# GD32A72_A74x register map
File version: 1.0
CPU: CM7 r2p1, little endian, MPU, FPU, DSP, 4 interrupt priority bits
Registers are 32-bit, read-write, reset 0x0 unless marked. A register's access mark holds for its fields unless they carry their own. Offsets are from the block's base; [hi:lo] are bit positions; {n}, {i} and the like mark numbered series.

## HSMIF
Base 0x49008C00
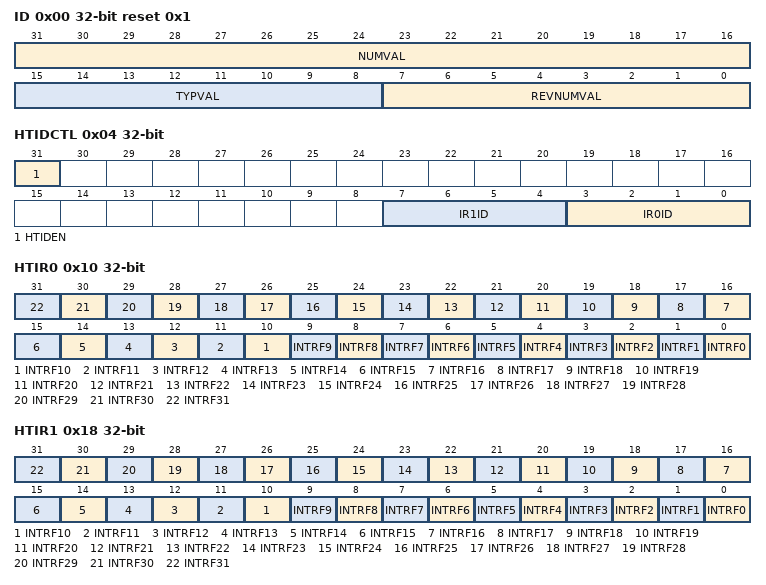
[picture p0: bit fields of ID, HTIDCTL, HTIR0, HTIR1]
0x00 ID ro reset 0x1 — Identifier register
  [31:16] NUMVAL — the value of the id number
  [15:8] TYPVAL — the value of the type
  [7:0] REVNUMVAL — the value of the type revision number
0x04 HTIDCTL ro — Host identifier control register
  [31] HTIDEN — host id enable
  [7:4] IR1ID — interrupt request1 id
  [3:0] IR0ID — interrupt request0 id
0x10 HTIR0 — Host interrupt request register0
  [n] INTRF{n} (n=0..31) — interrupt request flag {n}
0x18 HTIR1 — Host interrupt request register1
  [n] INTRF{n} (n=0..31) — interrupt request flag {n}
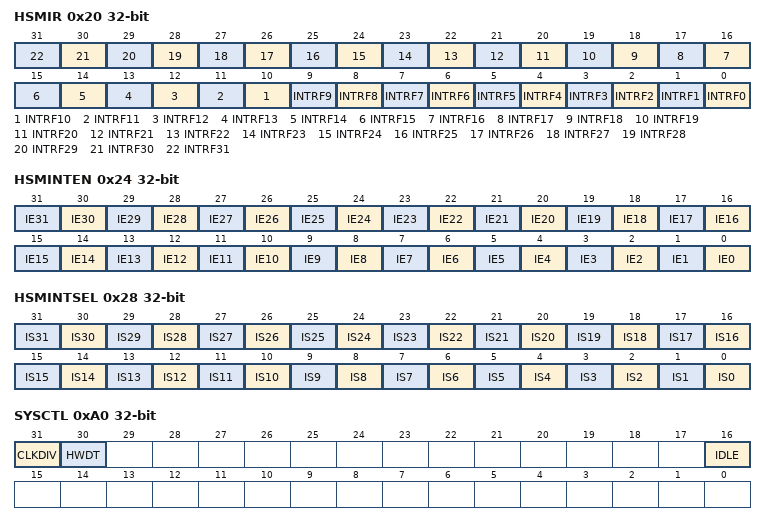
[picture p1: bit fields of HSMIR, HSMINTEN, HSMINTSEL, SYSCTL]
0x20 HSMIR — HSM interrupt request register
  [n] INTRF{n} (n=0..31) — interrupt request flag {n}
0x24 HSMINTEN — HSM interrupt enable register
  [n] IE{n} (n=0..31) — interrupt enable {n}
0x28 HSMINTSEL — HSM interrupt select register
  [n] IS{n} (n=0..31) — interrupt select {n}
0x40 HSMSTAT ro — HSM status register
  [31:0] STAT — status
0x48 HTSTAT — Host status register
  [31:0] STAT — status
0xA0 SYSCTL ro — System control register
  [31] CLKDIV — clock division
  [30] HWDT — HWDT widget
  [16] IDLE — idle state
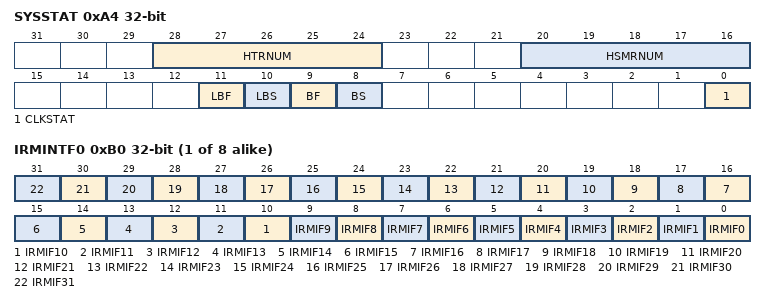
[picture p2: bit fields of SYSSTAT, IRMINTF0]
0xA4 SYSSTAT ro — System status register
  [28:24] HTRNUM — these bits indicate the number of host has performed software recovery in a power on reset (por) cycle
  [20:16] HSMRNUM — these bits indicate the number of hsm has performed software recovery in a power on reset (por) cycle
  [11] LBF — last boot failure flag
  [10] LBS — last boot success flag
  [9] BF — boot failure flag
  [8] BS — boot success flag
  [0] CLKSTAT — hsm sub system clock status
{0xB0+4i} IRMINTF{i} ro (i=0..7) — IRM interrupt flag register {i}
  [n] IRMIF{n} (n=0..31) — irm interrupt flag {n}

## HWSEM — Hardware semaphore
Base 0x49008800
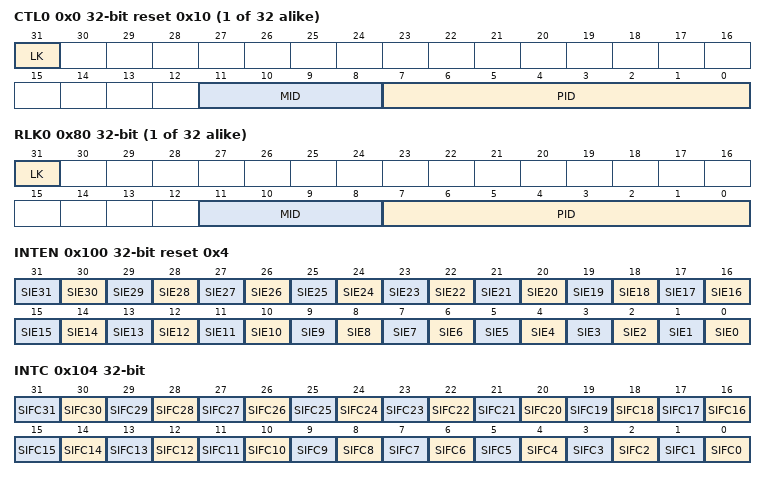
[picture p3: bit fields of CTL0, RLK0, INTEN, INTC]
{0x0+4i} CTL{i} reset 0x10 (i=0..31) — Control register {i}
  [31] LK — Lock semaphore
  [11:8] MID — AHB bus master identification
  [7:0] PID — Process identification
{0x80+4i} RLK{i} ro (i=0..31) — Read lock register {i}
  [31] LK — Lock semaphore by reading
  [11:8] MID — Bus master identification
  [7:0] PID — Process identification
0x100 INTEN reset 0x4 — Interrupt enable register
  [n] SIE{n} (n=0..31) — Semaphore interrupt enable bit {n}
0x104 INTC wo — Interrupt flag clear register
  [n] SIFC{n} (n=0..31) — Semaphore interrupt flag clear bit {n}
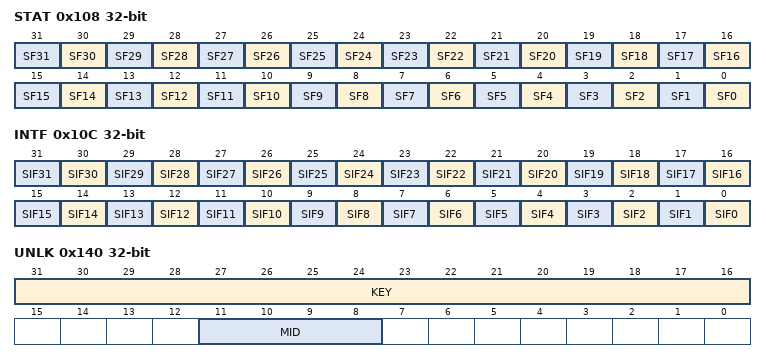
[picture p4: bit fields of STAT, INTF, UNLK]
0x108 STAT ro — Status register
  [n] SF{n} (n=0..31) — Semaphore flag {n}
0x10C INTF ro — Interrupt flag register
  [n] SIF{n} (n=0..31) — Semaphore interrupt flag {n}
0x140 UNLK wo — Unlock register
  [31:16] KEY — Key value
  [11:8] MID — Bus master identification to clear
0x144 KEY
  [31:16] KEY — Key for unlocking all semaphores of a bus master

## IMICU_BM1 — Interconnect matrix integrity check unit
Base 0x49009400
Same registers: IMICU_BM2 0x49009800
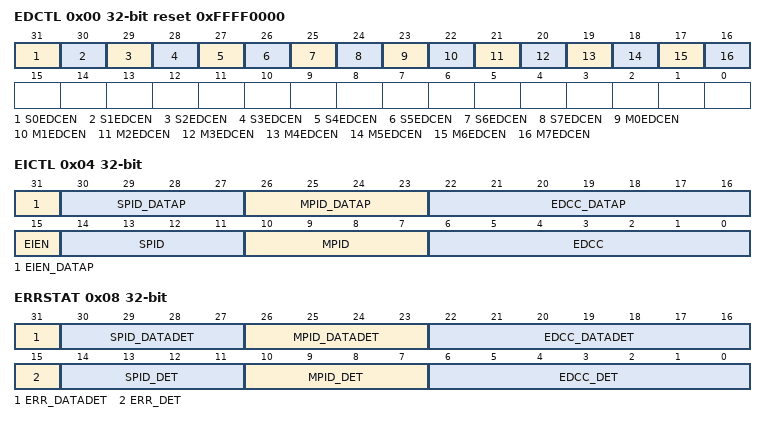
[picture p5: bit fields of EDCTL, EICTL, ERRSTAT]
0x00 EDCTL reset 0xFFFF0000 — Error dection control register
  [31-n] S{n}EDCEN (n=0..7) — Slave port {n} error detection enable bit
  [23-n] M{n}EDCEN (n=0..7) — Master port {n} error detection enable bit
0x04 EICTL — Error injection control register
  [31] EIEN_DATAP — Error injection function enable bit with data phase
  [30:27] SPID_DATAP — Target slave port ID
  [26:23] MPID_DATAP — Target master port ID
  [22:16] EDCC_DATAP — Calculated EDC code value with data phase
  [15] EIEN — Error injection function enable bit
  [14:11] SPID — Target slave port ID
  [10:7] MPID — Target master port ID
  [6:0] EDCC — Calculated EDC code value
0x08 ERRSTAT ro — Error status register
  [31] ERR_DATADET — Data phase error detected flag
  [30:27] SPID_DATADET — Target slave port with data phase error detected
  [26:23] MPID_DATADET — Target master port with data phase error detected
  [22:16] EDCC_DATADET — EDC code calculated with data phase error detected
  [15] ERR_DET — Error detected flag
  [14:11] SPID_DET — Target slave port with integrity check error detected
  [10:7] MPID_DET — Target master port with integrity check error detected
  [6:0] EDCC_DET — EDC code calculated with integrity check error detected
